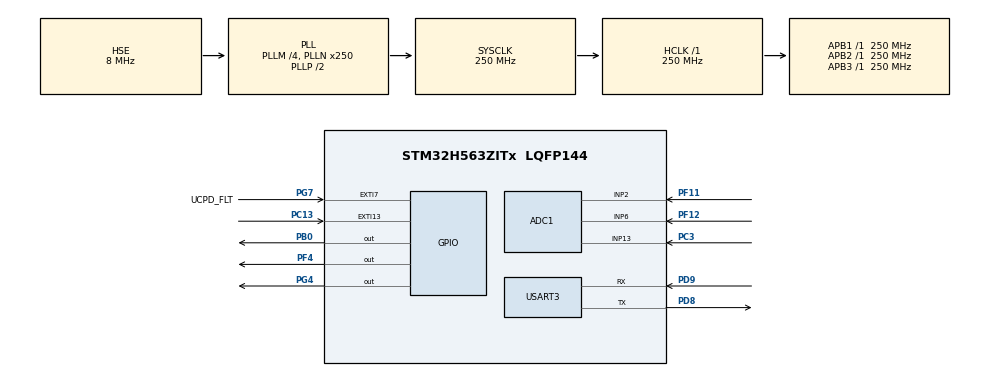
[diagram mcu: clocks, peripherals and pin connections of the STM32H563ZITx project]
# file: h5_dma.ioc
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ADC1.Channel-0\#ChannelRegularConversion=ADC_CHANNEL_2
ADC1.Channel-1\#ChannelRegularConversion=ADC_CHANNEL_6
ADC1.Channel-2\#ChannelRegularConversion=ADC_CHANNEL_13
ADC1.Channel-3\#ChannelRegularConversion=ADC_CHANNEL_2
ADC1.ClockPrescaler=ADC_CLOCK_ASYNC_DIV8
ADC1.ContinuousConvMode=ENABLE
ADC1.DMAContinuousRequests=ENABLE
ADC1.LowPowerAutoWait=ENABLE
ADC1.MonitoredBy-0\#ChannelRegularConversion=__NULL
ADC1.MonitoredBy-1\#ChannelRegularConversion=__NULL
ADC1.MonitoredBy-2\#ChannelRegularConversion=__NULL
ADC1.MonitoredBy-3\#ChannelRegularConversion=__NULL
ADC1.NbrOfConversion=4
ADC1.NbrOfConversionFlag=1
ADC1.OffsetNumber-0\#ChannelRegularConversion=ADC_OFFSET_NONE
ADC1.OffsetNumber-1\#ChannelRegularConversion=ADC_OFFSET_NONE
ADC1.OffsetNumber-2\#ChannelRegularConversion=ADC_OFFSET_NONE
ADC1.OffsetNumber-3\#ChannelRegularConversion=ADC_OFFSET_NONE
ADC1.Rank-0\#ChannelRegularConversion=1
ADC1.Rank-1\#ChannelRegularConversion=2
ADC1.Rank-2\#ChannelRegularConversion=3
ADC1.Rank-3\#ChannelRegularConversion=4
ADC1.SamplingTime-0\#ChannelRegularConversion=ADC_SAMPLETIME_2CYCLES_5
ADC1.SamplingTime-1\#ChannelRegularConversion=ADC_SAMPLETIME_2CYCLES_5
ADC1.SamplingTime-2\#ChannelRegularConversion=ADC_SAMPLETIME_2CYCLES_5
ADC1.SamplingTime-3\#ChannelRegularConversion=ADC_SAMPLETIME_2CYCLES_5
ADC1.master=1
BOOTPATH.BootPathName=LEGACY
BOOTPATH.UserSelectedBootPath=LEGACY
CORTEX_M33_NS.userName=CORTEX_M33
GPDMA1.LINKEDLISTMODE_GPDMACH6=DMA_LINKEDLIST_CIRCULAR
Linkedlist.MDMA_Channel0.GP_SW.0.ADDRESSING2D=DISABLE
Linkedlist.MDMA_Channel0.GP_SW.0.BlkHWRequest=DMA_BREQ_SINGLE_BURST
Linkedlist.MDMA_Channel0.GP_SW.0.DataHandling=NONE
Linkedlist.MDMA_Channel0.GP_SW.0.DataSize=(64*2)
Linkedlist.MDMA_Channel0.GP_SW.0.DestBurstLength=1
Linkedlist.MDMA_Channel0.GP_SW.0.DestDataWidth=DMA_DEST_DATAWIDTH_HALFWORD
Linkedlist.MDMA_Channel0.GP_SW.0.DestInc=DMA_DINC_INCREMENTED
Linkedlist.MDMA_Channel0.GP_SW.0.Direction=DMA_PERIPH_TO_MEMORY
Linkedlist.MDMA_Channel0.GP_SW.0.DstAddress=(uint32_t)data
Linkedlist.MDMA_Channel0.GP_SW.0.Instance=MDMA_Channel0
Linkedlist.MDMA_Channel0.GP_SW.0.LL_CIRCULARNODE=yourNodeName
Linkedlist.MDMA_Channel0.GP_SW.0.LL_MASTERDMA=GPDMA1_2D
Linkedlist.MDMA_Channel0.GP_SW.0.LL_NAME=YourQueueName
Linkedlist.MDMA_Channel0.GP_SW.0.LL_TYPE=CIRCULAR
Linkedlist.MDMA_Channel0.GP_SW.0.Mode=DMA_NORMAL
Linkedlist.MDMA_Channel0.GP_SW.0.NODE_NAME=YourNodeName
Linkedlist.MDMA_Channel0.GP_SW.0.Requestforcodegen=GPDMA1_REQUEST_ADC1
Linkedlist.MDMA_Channel0.GP_SW.0.SrcAddress=(uint32_t)&(ADC1->DR)
Linkedlist.MDMA_Channel0.GP_SW.0.SrcBurstLength=1
Linkedlist.MDMA_Channel0.GP_SW.0.SrcDataWidth=DMA_SRC_DATAWIDTH_HALFWORD
Linkedlist.MDMA_Channel0.GP_SW.0.SrcInc=DMA_SINC_FIXED
Linkedlist.MDMA_Channel0.GP_SW.0.TransferAllocatedPortSrc=DMA_SRC_ALLOCATED_PORT0
Linkedlist.MDMA_Channel0.GP_SW.0.TransferEventMode=DMA_TCEM_BLOCK_TRANSFER
Linkedlist.MDMA_Channel0.GP_SW.0.TriggerMode=DMA_TRIGM_BLOCK_TRANSFER
Linkedlist.MDMA_Channel0.GP_SW.0.TriggerPolarity=DMA_TRIG_POLARITY_RISING
Linkedlist.MDMA_Channel0.GP_SW.0.TriggerSelection=GPDMA1_TRIGGER_TIM15_TRGO
Linkedlist.MDMA_Channel0.GP_SW.1.ADDRESSING2D=DISABLE
Linkedlist.MDMA_Channel0.GP_SW.1.BlkHWRequest=DMA_BREQ_SINGLE_BURST
Linkedlist.MDMA_Channel0.GP_SW.1.DataHandling=NONE
Linkedlist.MDMA_Channel0.GP_SW.1.DataSize=(64*2)
Linkedlist.MDMA_Channel0.GP_SW.1.DestBurstLength=1
Linkedlist.MDMA_Channel0.GP_SW.1.DestDataWidth=DMA_DEST_DATAWIDTH_BYTE
Linkedlist.MDMA_Channel0.GP_SW.1.DestInc=DMA_DINC_FIXED
Linkedlist.MDMA_Channel0.GP_SW.1.Direction=DMA_MEMORY_TO_PERIPH
Linkedlist.MDMA_Channel0.GP_SW.1.DstAddress=(uint32_t)&(USART3->TDR)
Linkedlist.MDMA_Channel0.GP_SW.1.Instance=MDMA_Channel0
Linkedlist.MDMA_Channel0.GP_SW.1.LL_CIRCULARNODE=yourNodeName
Linkedlist.MDMA_Channel0.GP_SW.1.LL_MASTERDMA=GPDMA1_2D
Linkedlist.MDMA_Channel0.GP_SW.1.LL_NAME=YourQueueName
Linkedlist.MDMA_Channel0.GP_SW.1.LL_TYPE=CIRCULAR
Linkedlist.MDMA_Channel0.GP_SW.1.Mode=DMA_NORMAL
Linkedlist.MDMA_Channel0.GP_SW.1.NODE_NAME=YourNodeName2
Linkedlist.MDMA_Channel0.GP_SW.1.Requestforcodegen=GPDMA1_REQUEST_USART3_TX
Linkedlist.MDMA_Channel0.GP_SW.1.SrcAddress=(uint32_t)data
Linkedlist.MDMA_Channel0.GP_SW.1.SrcBurstLength=1
Linkedlist.MDMA_Channel0.GP_SW.1.SrcDataWidth=DMA_SRC_DATAWIDTH_BYTE
Linkedlist.MDMA_Channel0.GP_SW.1.SrcInc=DMA_SINC_INCREMENTED
Linkedlist.MDMA_Channel0.GP_SW.1.TransferAllocatedPortSrc=DMA_SRC_ALLOCATED_PORT0
Linkedlist.MDMA_Channel0.GP_SW.1.TransferEventMode=DMA_TCEM_BLOCK_TRANSFER
Linkedlist.MDMA_Channel0.GP_SW.1.TriggerPolarity=DMA_TRIG_POLARITY_MASKED
Linkedlist.MDMA_Channel0.Request0=GP_SW
Linkedlist.MDMA_Channel0.Request1=GP_SW
Linkedlist.MDMA_Channel0.RequestsNb=2
Linkedlist.RequestSet0=MDMA_Channel0
Linkedlist.RequestSetsNb=1
Mcu.Family=STM32H5
Mcu.Name=STM32H563ZITx
Mcu.Package=LQFP144
NVIC.PriorityGroup=NVIC_PRIORITYGROUP_4
PA1.GPIO_Label=RMII_REF_CLK
PA1.GPIO_Mode=GPIO_MODE_AF_PP
PA1.GPIO_PuPd=GPIO_NOPULL
PA1.GPIO_Speed=GPIO_SPEED_FREQ_LOW
PA1.Signal=ETH_REF_CLK
PA11.GPIO_Label=USB_FS_N
PA11.Signal=USB_DM
PA12.GPIO_Label=USB_FS_P
PA12.Signal=USB_DP
PA13(JTMS/SWDIO).GPIO_Label=SWDIO
PA13(JTMS/SWDIO).Signal=DEBUG_JTMS-SWDIO
PA14(JTCK/SWCLK).GPIO_Label=SWCLK
PA14(JTCK/SWCLK).Signal=DEBUG_JTCK-SWCLK
PA15(JTDI).GPIO_Label=T_JTDI
PA15(JTDI).Signal=DEBUG_JTDI
PA2.GPIO_Label=RMII_MDIO
PA2.GPIO_Mode=GPIO_MODE_AF_PP
PA2.GPIO_PuPd=GPIO_NOPULL
PA2.GPIO_Speed=GPIO_SPEED_FREQ_LOW
PA2.Signal=ETH_MDIO
PA4.GPIO_Label=VBUS_SENSE
PA4.Signal=ADCx_INP18
PA7.GPIO_Label=RMII_CRS_DV
PA7.GPIO_Mode=GPIO_MODE_AF_PP
PA7.GPIO_PuPd=GPIO_NOPULL
PA7.GPIO_Speed=GPIO_SPEED_FREQ_LOW
PA7.Signal=ETH_CRS_DV
PA9.GPIO_Label=UCDP_DBn
PA9.Signal=UCPD1_DB1
PB0.Signal=GPIO_Output
PB13.GPIO_Label=UCPD_CC1
PB13.Signal=UCPD1_CC1
PB14.GPIO_Label=UCPD_CC2
PB14.Signal=UCPD1_CC2
PB15.GPIO_Label=RMII_TXD1
PB15.GPIO_Mode=GPIO_MODE_AF_PP
PB15.GPIO_PuPd=GPIO_NOPULL
PB15.GPIO_Speed=GPIO_SPEED_FREQ_LOW
PB15.Signal=ETH_TXD1
PB3(JTDO/TRACESWO).GPIO_Label=SWO
PB3(JTDO/TRACESWO).Signal=DEBUG_JTDO-SWO
PB6.GPIO_Label=ARD_D1_TX
PB6.Signal=LPUART1_TX
PB7.GPIO_Label=ARD_D0_RX
PB7.Signal=LPUART1_RX
PC1.GPIO_Label=RMII_MDC
PC1.GPIO_Mode=GPIO_MODE_AF_PP
PC1.GPIO_PuPd=GPIO_NOPULL
PC1.GPIO_Speed=GPIO_SPEED_FREQ_LOW
PC1.Signal=ETH_MDC
PC13.Signal=GPXTI13
PC14-OSC32_IN(OSC32_IN).Mode=LSE-External-Oscillator
PC14-OSC32_IN(OSC32_IN).Signal=RCC_OSC32_IN
PC15-OSC32_OUT(OSC32_OUT).Mode=LSE-External-Oscillator
PC15-OSC32_OUT(OSC32_OUT).Signal=RCC_OSC32_OUT
PC3.Signal=ADCx_INP13
PC4.GPIO_Label=RMII_RXD0
PC4.GPIO_Mode=GPIO_MODE_AF_PP
PC4.GPIO_PuPd=GPIO_NOPULL
PC4.GPIO_Speed=GPIO_SPEED_FREQ_LOW
PC4.Signal=ETH_RXD0
PC5.GPIO_Label=RMII_RXD1
PC5.GPIO_Mode=GPIO_MODE_AF_PP
PC5.GPIO_PuPd=GPIO_NOPULL
PC5.GPIO_Speed=GPIO_SPEED_FREQ_LOW
PC5.Signal=ETH_RXD1
PD8.Mode=Asynchronous
PD8.Signal=USART3_TX
PD9.Mode=Asynchronous
PD9.Signal=USART3_RX
PE2.GPIO_Label=TRACE_CK
PE2.Signal=DEBUG_TRACECLK
PE3.GPIO_Label=TRACE_D0
PE3.Signal=DEBUG_TRACED0
PE4.GPIO_Label=TRACE_D1
PE4.Signal=DEBUG_TRACED1
PE5.GPIO_Label=TRACE_D2
PE5.Signal=DEBUG_TRACED2
PE6.GPIO_Label=TRACE_D3
PE6.Signal=DEBUG_TRACED3
PF11.Mode=IN2-Single-Ended
PF11.Signal=ADC1_INP2
PF12.Mode=IN6-Single-Ended
PF12.Signal=ADC1_INP6
PF4.Signal=GPIO_Output
PG11.GPIO_Label=RMII_TXT_EN
PG11.GPIO_Mode=GPIO_MODE_AF_PP
PG11.GPIO_PuPd=GPIO_NOPULL
PG11.GPIO_Speed=GPIO_SPEED_FREQ_LOW
PG11.Signal=ETH_TX_EN
PG13.GPIO_Label=RMI_TXD0
PG13.GPIO_Mode=GPIO_MODE_AF_PP
PG13.GPIO_PuPd=GPIO_NOPULL
PG13.GPIO_Speed=GPIO_SPEED_FREQ_LOW
PG13.Signal=ETH_TXD0
PG4.Signal=GPIO_Output
PG7.GPIO_Label=UCPD_FLT
PG7.Signal=GPXTI7
PH0-OSC_IN(PH0).GPIO_Label=STLK_MCO
PH0-OSC_IN(PH0).Mode=HSE-External-Clock-Source
PH0-OSC_IN(PH0).Signal=RCC_OSC_IN
ProjectManager.HeapSize=0x200
ProjectManager.StackSize=0x400
ProjectManager.TargetToolchain=STM32CubeIDE
RCC.ADCFreq_Value=250000000
RCC.AHBFreq_Value=250000000
RCC.APB1Freq_Value=250000000
RCC.APB1TimFreq_Value=250000000
RCC.APB2Freq_Value=250000000
RCC.APB2TimFreq_Value=250000000
RCC.APB3Freq_Value=250000000
RCC.CSI_VALUE=4000000
RCC.CortexFreq_Value=250000000
RCC.EPOD_VALUE=8000000
RCC.HCLKFreq_Value=250000000
RCC.HSE_VALUE=8000000
RCC.HSI48_VALUE=48000000
RCC.HSIDiv=RCC_HSI_DIV1
RCC.HSI_VALUE=64000000
RCC.LSIRC_VALUE=32000
RCC.PLLM=4
RCC.PLLN=250
RCC.PLLSourceVirtual=RCC_PLL1_SOURCE_HSE
RCC.SYSCLKFreq_VALUE=250000000
RCC.SYSCLKSource=RCC_SYSCLKSOURCE_PLLCLK
RCC.USBFreq_Value=48000000
RCC.VCOOutputFreq_Value=500000000
SH.ADCx_INP13.0=ADC1_INP13,IN13-Single-Ended
SH.ADCx_INP18.0=ADC1_INP18
TIM15.PeriodNoDither=4999
TIM15.Prescaler=49999
TIM15.TIM_MasterOutputTrigger=TIM_TRGO_UPDATE
USART3.VirtualMode=VM_ASYNC
VP_BOOTPATH_VS_BOOTPATH.Mode=BP_Activate
VP_CORTEX_M33_NS_VS_Hclk.Mode=Hclk_Mode
VP_GPDMA1_VS_GPDMACH6.Mode=LINKEDLIST_GPDMACH6
VP_MEMORYMAP_VS_MEMORYMAP.Mode=CurAppReg
VP_PWR_VS_DBSignals.Mode=DisableDeadBatterySignals
VP_PWR_VS_LPOM.Mode=PowerOptimisation
VP_PWR_VS_SECSignals.Mode=Security/Privilege
VP_TIM15_VS_ClockSourceINT.Mode=Internal
board=NUCLEO-H563ZI

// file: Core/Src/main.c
/* USER CODE BEGIN Header */
/**
  ******************************************************************************
  * @file           : main.c
  * @brief          : Main program body
  ******************************************************************************
  * @attention
  *
  * Copyright (c) 2024 STMicroelectronics.
  * All rights reserved.
  *
  * This software is licensed under terms that can be found in the LICENSE file
  * in the root directory of this software component.
  * If no LICENSE file comes with this software, it is provided AS-IS.
  *
  ******************************************************************************
  */
/* USER CODE END Header */
#include "main.h"
#include "linked_list.h"

ADC_HandleTypeDef hadc1;

DMA_HandleTypeDef handle_GPDMA1_Channel6;

TIM_HandleTypeDef htim15;

UART_HandleTypeDef huart3;

/* USER CODE BEGIN PV */
uint16_t data[64];
extern DMA_QListTypeDef YourQueueName;
/* USER CODE END PV */

void SystemClock_Config(void);
static void MX_GPIO_Init(void);
static void MX_GPDMA1_Init(void);
static void MX_ADC1_Init(void);
static void MX_TIM15_Init(void);
static void MX_USART3_UART_Init(void);

int main(void)
{

  /* MCU Configuration--------------------------------------------------------*/

  /* Reset of all peripherals, Initializes the Flash interface and the Systick. */
  HAL_Init();

  /* Configure the system clock */
  SystemClock_Config();

  /* Initialize all configured peripherals */
  MX_GPIO_Init();
  MX_GPDMA1_Init();
  MX_ADC1_Init();
  MX_TIM15_Init();
  MX_USART3_UART_Init();
  /* USER CODE BEGIN 2 */
  //Setup and initialization of Linked list DMA
   MX_YourQueueName_Config();
   HAL_DMAEx_List_LinkQ(&handle_GPDMA1_Channel6, &YourQueueName);

   // USART3 will be controlled by DMA, therefore we enable it by direct register access
   ATOMIC_SET_BIT(huart3.Instance->CR3, USART_CR3_DMAT);
   __HAL_UART_ENABLE(&huart3);

   //Enable Linked list DMA
   HAL_DMAEx_List_Start(&handle_GPDMA1_Channel6);
   // using of Linked List DMA requires special procedure (HAL library supports standard request mede currently)
   ADC1->CFGR |= ADC_CFGR_DMAEN;
   HAL_ADC_Start(&hadc1);

   // Start TIM15 for triggering
   HAL_TIM_Base_Start(&htim15);
  /* USER CODE END 2 */

  /* Infinite loop */
  while (1)
  {

  }
}

void SystemClock_Config(void)
{
  RCC_OscInitTypeDef RCC_OscInitStruct = {0};
  RCC_ClkInitTypeDef RCC_ClkInitStruct = {0};

  /** Configure the main internal regulator output voltage
  */
  __HAL_PWR_VOLTAGESCALING_CONFIG(PWR_REGULATOR_VOLTAGE_SCALE0);

  while(!__HAL_PWR_GET_FLAG(PWR_FLAG_VOSRDY)) {}

  /** Initializes the RCC Oscillators according to the specified parameters
  * in the RCC_OscInitTypeDef structure.
  */
  RCC_OscInitStruct.OscillatorType = RCC_OSCILLATORTYPE_HSE;
  RCC_OscInitStruct.HSEState = RCC_HSE_BYPASS;
  RCC_OscInitStruct.PLL.PLLState = RCC_PLL_ON;
  RCC_OscInitStruct.PLL.PLLSource = RCC_PLL1_SOURCE_HSE;
  RCC_OscInitStruct.PLL.PLLM = 4;
  RCC_OscInitStruct.PLL.PLLN = 250;
  RCC_OscInitStruct.PLL.PLLP = 2;
  RCC_OscInitStruct.PLL.PLLQ = 2;
  RCC_OscInitStruct.PLL.PLLR = 2;
  RCC_OscInitStruct.PLL.PLLRGE = RCC_PLL1_VCIRANGE_1;
  RCC_OscInitStruct.PLL.PLLVCOSEL = RCC_PLL1_VCORANGE_WIDE;
  RCC_OscInitStruct.PLL.PLLFRACN = 0;
  if (HAL_RCC_OscConfig(&RCC_OscInitStruct) != HAL_OK)
  {
    Error_Handler();
  }

  /** Initializes the CPU, AHB and APB buses clocks
  */
  RCC_ClkInitStruct.ClockType = RCC_CLOCKTYPE_HCLK|RCC_CLOCKTYPE_SYSCLK
                              |RCC_CLOCKTYPE_PCLK1|RCC_CLOCKTYPE_PCLK2
                              |RCC_CLOCKTYPE_PCLK3;
  RCC_ClkInitStruct.SYSCLKSource = RCC_SYSCLKSOURCE_PLLCLK;
  RCC_ClkInitStruct.AHBCLKDivider = RCC_SYSCLK_DIV1;
  RCC_ClkInitStruct.APB1CLKDivider = RCC_HCLK_DIV1;
  RCC_ClkInitStruct.APB2CLKDivider = RCC_HCLK_DIV1;
  RCC_ClkInitStruct.APB3CLKDivider = RCC_HCLK_DIV1;

  if (HAL_RCC_ClockConfig(&RCC_ClkInitStruct, FLASH_LATENCY_5) != HAL_OK)
  {
    Error_Handler();
  }
}

static void MX_ADC1_Init(void)
{

  ADC_ChannelConfTypeDef sConfig = {0};

  /** Common config
  */
  hadc1.Instance = ADC1;
  hadc1.Init.ClockPrescaler = ADC_CLOCK_ASYNC_DIV8;
  hadc1.Init.Resolution = ADC_RESOLUTION_12B;
  hadc1.Init.DataAlign = ADC_DATAALIGN_RIGHT;
  hadc1.Init.ScanConvMode = ADC_SCAN_ENABLE;
  hadc1.Init.EOCSelection = ADC_EOC_SINGLE_CONV;
  hadc1.Init.LowPowerAutoWait = ENABLE;
  hadc1.Init.ContinuousConvMode = ENABLE;
  hadc1.Init.NbrOfConversion = 4;
  hadc1.Init.DiscontinuousConvMode = DISABLE;
  hadc1.Init.ExternalTrigConv = ADC_SOFTWARE_START;
  hadc1.Init.ExternalTrigConvEdge = ADC_EXTERNALTRIGCONVEDGE_NONE;
  hadc1.Init.DMAContinuousRequests = ENABLE;
  hadc1.Init.SamplingMode = ADC_SAMPLING_MODE_NORMAL;
  hadc1.Init.Overrun = ADC_OVR_DATA_PRESERVED;
  hadc1.Init.OversamplingMode = DISABLE;
  if (HAL_ADC_Init(&hadc1) != HAL_OK)
  {
    Error_Handler();
  }

  /** Configure Regular Channel
  */
  sConfig.Channel = ADC_CHANNEL_2;
  sConfig.Rank = ADC_REGULAR_RANK_1;
  sConfig.SamplingTime = ADC_SAMPLETIME_2CYCLES_5;
  sConfig.SingleDiff = ADC_SINGLE_ENDED;
  sConfig.OffsetNumber = ADC_OFFSET_NONE;
  sConfig.Offset = 0;
  if (HAL_ADC_ConfigChannel(&hadc1, &sConfig) != HAL_OK)
  {
    Error_Handler();
  }

  /** Configure Regular Channel
  */
  sConfig.Channel = ADC_CHANNEL_6;
  sConfig.Rank = ADC_REGULAR_RANK_2;
  if (HAL_ADC_ConfigChannel(&hadc1, &sConfig) != HAL_OK)
  {
    Error_Handler();
  }

  /** Configure Regular Channel
  */
  sConfig.Channel = ADC_CHANNEL_13;
  sConfig.Rank = ADC_REGULAR_RANK_3;
  if (HAL_ADC_ConfigChannel(&hadc1, &sConfig) != HAL_OK)
  {
    Error_Handler();
  }

  /** Configure Regular Channel
  */
  sConfig.Channel = ADC_CHANNEL_2;
  sConfig.Rank = ADC_REGULAR_RANK_4;
  if (HAL_ADC_ConfigChannel(&hadc1, &sConfig) != HAL_OK)
  {
    Error_Handler();
  }

}

static void MX_GPDMA1_Init(void)
{

  /* Peripheral clock enable */
  __HAL_RCC_GPDMA1_CLK_ENABLE();

  handle_GPDMA1_Channel6.Instance = GPDMA1_Channel6;
  handle_GPDMA1_Channel6.InitLinkedList.Priority = DMA_LOW_PRIORITY_LOW_WEIGHT;
  handle_GPDMA1_Channel6.InitLinkedList.LinkStepMode = DMA_LSM_FULL_EXECUTION;
  handle_GPDMA1_Channel6.InitLinkedList.LinkAllocatedPort = DMA_LINK_ALLOCATED_PORT0;
  handle_GPDMA1_Channel6.InitLinkedList.TransferEventMode = DMA_TCEM_LAST_LL_ITEM_TRANSFER;
  handle_GPDMA1_Channel6.InitLinkedList.LinkedListMode = DMA_LINKEDLIST_CIRCULAR;
  if (HAL_DMAEx_List_Init(&handle_GPDMA1_Channel6) != HAL_OK)
  {
    Error_Handler();
  }
  if (HAL_DMA_ConfigChannelAttributes(&handle_GPDMA1_Channel6, DMA_CHANNEL_NPRIV) != HAL_OK)
  {
    Error_Handler();
  }

}

static void MX_TIM15_Init(void)
{

  TIM_ClockConfigTypeDef sClockSourceConfig = {0};
  TIM_MasterConfigTypeDef sMasterConfig = {0};

  htim15.Instance = TIM15;
  htim15.Init.Prescaler = 49999;
  htim15.Init.CounterMode = TIM_COUNTERMODE_UP;
  htim15.Init.Period = 4999;
  htim15.Init.ClockDivision = TIM_CLOCKDIVISION_DIV1;
  htim15.Init.RepetitionCounter = 0;
  htim15.Init.AutoReloadPreload = TIM_AUTORELOAD_PRELOAD_DISABLE;
  if (HAL_TIM_Base_Init(&htim15) != HAL_OK)
  {
    Error_Handler();
  }
  sClockSourceConfig.ClockSource = TIM_CLOCKSOURCE_INTERNAL;
  if (HAL_TIM_ConfigClockSource(&htim15, &sClockSourceConfig) != HAL_OK)
  {
    Error_Handler();
  }
  sMasterConfig.MasterOutputTrigger = TIM_TRGO_UPDATE;
  sMasterConfig.MasterSlaveMode = TIM_MASTERSLAVEMODE_DISABLE;
  if (HAL_TIMEx_MasterConfigSynchronization(&htim15, &sMasterConfig) != HAL_OK)
  {
    Error_Handler();
  }

}

static void MX_USART3_UART_Init(void)
{

  huart3.Instance = USART3;
  huart3.Init.BaudRate = 115200;
  huart3.Init.WordLength = UART_WORDLENGTH_8B;
  huart3.Init.StopBits = UART_STOPBITS_1;
  huart3.Init.Parity = UART_PARITY_NONE;
  huart3.Init.Mode = UART_MODE_TX_RX;
  huart3.Init.HwFlowCtl = UART_HWCONTROL_NONE;
  huart3.Init.OverSampling = UART_OVERSAMPLING_16;
  huart3.Init.OneBitSampling = UART_ONE_BIT_SAMPLE_DISABLE;
  huart3.Init.ClockPrescaler = UART_PRESCALER_DIV1;
  huart3.AdvancedInit.AdvFeatureInit = UART_ADVFEATURE_NO_INIT;
  if (HAL_UART_Init(&huart3) != HAL_OK)
  {
    Error_Handler();
  }
  if (HAL_UARTEx_SetTxFifoThreshold(&huart3, UART_TXFIFO_THRESHOLD_1_8) != HAL_OK)
  {
    Error_Handler();
  }
  if (HAL_UARTEx_SetRxFifoThreshold(&huart3, UART_RXFIFO_THRESHOLD_1_8) != HAL_OK)
  {
    Error_Handler();
  }
  if (HAL_UARTEx_DisableFifoMode(&huart3) != HAL_OK)
  {
    Error_Handler();
  }

}

static void MX_GPIO_Init(void)
{
  GPIO_InitTypeDef GPIO_InitStruct = {0};

  /* GPIO Ports Clock Enable */
  __HAL_RCC_GPIOE_CLK_ENABLE();
  __HAL_RCC_GPIOC_CLK_ENABLE();
  __HAL_RCC_GPIOF_CLK_ENABLE();
  __HAL_RCC_GPIOH_CLK_ENABLE();
  __HAL_RCC_GPIOA_CLK_ENABLE();
  __HAL_RCC_GPIOB_CLK_ENABLE();
  __HAL_RCC_GPIOD_CLK_ENABLE();
  __HAL_RCC_GPIOG_CLK_ENABLE();

  /*Configure GPIO pin Output Level */
  HAL_GPIO_WritePin(GPIOF, GPIO_PIN_4, GPIO_PIN_RESET);

  /*Configure GPIO pin Output Level */
  HAL_GPIO_WritePin(GPIOB, GPIO_PIN_0, GPIO_PIN_RESET);

  /*Configure GPIO pin Output Level */
  HAL_GPIO_WritePin(GPIOG, GPIO_PIN_4, GPIO_PIN_RESET);

  /*Configure GPIO pin : PC13 */
  GPIO_InitStruct.Pin = GPIO_PIN_13;
  GPIO_InitStruct.Mode = GPIO_MODE_IT_RISING;
  GPIO_InitStruct.Pull = GPIO_NOPULL;
  HAL_GPIO_Init(GPIOC, &GPIO_InitStruct);

  /*Configure GPIO pin : PF4 */
  GPIO_InitStruct.Pin = GPIO_PIN_4;
  GPIO_InitStruct.Mode = GPIO_MODE_OUTPUT_PP;
  GPIO_InitStruct.Pull = GPIO_NOPULL;
  GPIO_InitStruct.Speed = GPIO_SPEED_FREQ_LOW;
  HAL_GPIO_Init(GPIOF, &GPIO_InitStruct);

  /*Configure GPIO pins : RMII_MDC_Pin RMII_RXD0_Pin RMII_RXD1_Pin */
  GPIO_InitStruct.Pin = RMII_MDC_Pin|RMII_RXD0_Pin|RMII_RXD1_Pin;
  GPIO_InitStruct.Mode = GPIO_MODE_AF_PP;
  GPIO_InitStruct.Pull = GPIO_NOPULL;
  GPIO_InitStruct.Speed = GPIO_SPEED_FREQ_HIGH;
  GPIO_InitStruct.Alternate = GPIO_AF11_ETH;
  HAL_GPIO_Init(GPIOC, &GPIO_InitStruct);

  /*Configure GPIO pins : RMII_REF_CLK_Pin RMII_MDIO_Pin RMII_CRS_DV_Pin */
  GPIO_InitStruct.Pin = RMII_REF_CLK_Pin|RMII_MDIO_Pin|RMII_CRS_DV_Pin;
  GPIO_InitStruct.Mode = GPIO_MODE_AF_PP;
  GPIO_InitStruct.Pull = GPIO_NOPULL;
  GPIO_InitStruct.Speed = GPIO_SPEED_FREQ_HIGH;
  GPIO_InitStruct.Alternate = GPIO_AF11_ETH;
  HAL_GPIO_Init(GPIOA, &GPIO_InitStruct);

  /*Configure GPIO pin : PB0 */
  GPIO_InitStruct.Pin = GPIO_PIN_0;
  GPIO_InitStruct.Mode = GPIO_MODE_OUTPUT_PP;
  GPIO_InitStruct.Pull = GPIO_NOPULL;
  GPIO_InitStruct.Speed = GPIO_SPEED_FREQ_LOW;
  HAL_GPIO_Init(GPIOB, &GPIO_InitStruct);

  /*Configure GPIO pins : UCPD_CC1_Pin UCPD_CC2_Pin */
  GPIO_InitStruct.Pin = UCPD_CC1_Pin|UCPD_CC2_Pin;
  GPIO_InitStruct.Mode = GPIO_MODE_ANALOG;
  GPIO_InitStruct.Pull = GPIO_NOPULL;
  HAL_GPIO_Init(GPIOB, &GPIO_InitStruct);

  /*Configure GPIO pin : RMII_TXD1_Pin */
  GPIO_InitStruct.Pin = RMII_TXD1_Pin;
  GPIO_InitStruct.Mode = GPIO_MODE_AF_PP;
  GPIO_InitStruct.Pull = GPIO_NOPULL;
  GPIO_InitStruct.Speed = GPIO_SPEED_FREQ_HIGH;
  GPIO_InitStruct.Alternate = GPIO_AF11_ETH;
  HAL_GPIO_Init(RMII_TXD1_GPIO_Port, &GPIO_InitStruct);

  /*Configure GPIO pin : PG4 */
  GPIO_InitStruct.Pin = GPIO_PIN_4;
  GPIO_InitStruct.Mode = GPIO_MODE_OUTPUT_PP;
  GPIO_InitStruct.Pull = GPIO_NOPULL;
  GPIO_InitStruct.Speed = GPIO_SPEED_FREQ_LOW;
  HAL_GPIO_Init(GPIOG, &GPIO_InitStruct);

  /*Configure GPIO pin : UCPD_FLT_Pin */
  GPIO_InitStruct.Pin = UCPD_FLT_Pin;
  GPIO_InitStruct.Mode = GPIO_MODE_IT_RISING;
  GPIO_InitStruct.Pull = GPIO_NOPULL;
  HAL_GPIO_Init(UCPD_FLT_GPIO_Port, &GPIO_InitStruct);

  /*Configure GPIO pins : USB_FS_N_Pin USB_FS_P_Pin */
  GPIO_InitStruct.Pin = USB_FS_N_Pin|USB_FS_P_Pin;
  GPIO_InitStruct.Mode = GPIO_MODE_AF_PP;
  GPIO_InitStruct.Pull = GPIO_NOPULL;
  GPIO_InitStruct.Speed = GPIO_SPEED_FREQ_LOW;
  GPIO_InitStruct.Alternate = GPIO_AF10_USB;
  HAL_GPIO_Init(GPIOA, &GPIO_InitStruct);

  /*Configure GPIO pins : RMII_TXT_EN_Pin RMI_TXD0_Pin */
  GPIO_InitStruct.Pin = RMII_TXT_EN_Pin|RMI_TXD0_Pin;
  GPIO_InitStruct.Mode = GPIO_MODE_AF_PP;
  GPIO_InitStruct.Pull = GPIO_NOPULL;
  GPIO_InitStruct.Speed = GPIO_SPEED_FREQ_HIGH;
  GPIO_InitStruct.Alternate = GPIO_AF11_ETH;
  HAL_GPIO_Init(GPIOG, &GPIO_InitStruct);

  /*Configure GPIO pins : ARD_D1_TX_Pin ARD_D0_RX_Pin */
  GPIO_InitStruct.Pin = ARD_D1_TX_Pin|ARD_D0_RX_Pin;
  GPIO_InitStruct.Mode = GPIO_MODE_AF_PP;
  GPIO_InitStruct.Pull = GPIO_NOPULL;
  GPIO_InitStruct.Speed = GPIO_SPEED_FREQ_LOW;
  GPIO_InitStruct.Alternate = GPIO_AF8_LPUART1;
  HAL_GPIO_Init(GPIOB, &GPIO_InitStruct);

}

void Error_Handler(void)
{
  __disable_irq();
  while (1)
  {
  }
}
